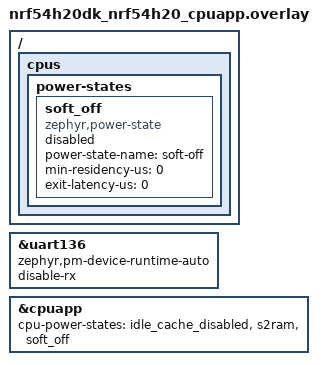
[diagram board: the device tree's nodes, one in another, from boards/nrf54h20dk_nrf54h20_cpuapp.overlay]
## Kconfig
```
# Copyright (c) 2021 Nordic Semiconductor ASA
# SPDX-License-Identifier: Apache-2.0

mainmenu "Nordic SYSTEM_OFF demo"

config APP_USE_RETAINED_MEM
	bool "Use state retention in system off using retained_mem driver"
	select RETAINED_MEM

config GRTC_WAKEUP_ENABLE
	bool "Use GRTC to wake up device from system off"
	default n
	help
	  Switch wake up source from pressing sw0 button to GRTC

source "Kconfig.zephyr"
```

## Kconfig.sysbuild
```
# Copyright 2024 Nordic Semiconductor ASA
#
# SPDX-License-Identifier: Apache-2.0

source "share/sysbuild/Kconfig"

config REMOTE_CORE_BOARD
string
	default "nrf54h20dk/nrf54h20/cpurad" if $(BOARD) = "nrf54h20dk"
```

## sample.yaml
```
sample:
  name: Low Power State Sample for nRF5x
common:
  tags: power
tests:
  sample.boards.nrf.system_off:
    integration_platforms:
      - nrf52840dk/nrf52840
    platform_allow:
      - nrf51dk/nrf51822
      - nrf52840dk/nrf52840
      - nrf52dk/nrf52832
      - nrf5340dk/nrf5340/cpuapp
      - nrf54l15dk/nrf54l05/cpuapp
      - nrf54l15dk/nrf54l10/cpuapp
      - nrf54l15dk/nrf54l15/cpuapp
      - nrf54lm20dk/nrf54lm20a/cpuapp
      - nrf54lm20dk/nrf54lm20b/cpuapp
      - nrf7120dk/nrf7120/cpuapp
    harness: console
    harness_config:
      type: multi_line
      ordered: true
      regex:
        - "system off demo"
        - "Retained data not supported"
        - "Entering system off; press sw0 to restart"
  sample.boards.nrf.system_off.retained_mem:
    integration_platforms:
      - nrf52840dk/nrf52840
    platform_allow:
      - nrf52840dk/nrf52840
      - nrf52dk/nrf52832
      - nrf5340dk/nrf5340/cpuapp
      - nrf54l15dk/nrf54l05/cpuapp
      - nrf54l15dk/nrf54l10/cpuapp
      - nrf54l15dk/nrf54l15/cpuapp
      - nrf54lm20dk/nrf54lm20a/cpuapp
      - nrf54lm20dk/nrf54lm20b/cpuapp
      - nrf7120dk/nrf7120/cpuapp
    extra_configs:
      - CONFIG_APP_USE_RETAINED_MEM=y
    harness: console
    harness_config:
      type: multi_line
      ordered: true
      regex:
        - "system off demo"
        - "Retained data: valid"
        - "Boot count: 1"
        - "Off count: 0"
        - "Active Ticks:"
        - "Entering system off; press sw0 to restart"
  sample.boards.nrf.system_off.grtc_off:
    platform_allow:
      - nrf54l15dk/nrf54l05/cpuapp
      - nrf54l15dk/nrf54l10/cpuapp
      - nrf54l15dk/nrf54l15/cpuapp
      - nrf54lm20dk/nrf54lm20a/cpuapp
      - nrf54lm20dk/nrf54lm20b/cpuapp
      - nrf7120dk/nrf7120/cpuapp
    extra_configs:
      - CONFIG_SYS_CLOCK_DISABLE=y
    harness: console
    harness_config:
      type: multi_line
      ordered: true
      regex:
        - "system off demo"
        - "Retained data not supported"
        - "System clock will be disabled"
        - "Entering system off; press sw0 to restart"
  sample.boards.nrf.system_off.retained_mem.grtc_off:
    platform_allow:
      - nrf54l15dk/nrf54l05/cpuapp
      - nrf54l15dk/nrf54l10/cpuapp
      - nrf54l15dk/nrf54l15/cpuapp
      - nrf54lm20dk/nrf54lm20a/cpuapp
      - nrf54lm20dk/nrf54lm20b/cpuapp
      - nrf7120dk/nrf7120/cpuapp
    extra_configs:
      - CONFIG_APP_USE_RETAINED_MEM=y
      - CONFIG_SYS_CLOCK_DISABLE=y
    harness: console
    harness_config:
      type: multi_line
      ordered: true
      regex:
        - "system off demo"
        - "Retained data: valid"
        - "Boot count: 1"
        - "Off count: 0"
        - "Active Ticks:"
        - "System clock will be disabled"
        - "Entering system off; press sw0 to restart"
  sample.boards.nrf.system_off.grtc_wakeup:
    platform_allow:
      - nrf54l15dk/nrf54l05/cpuapp
      - nrf54l15dk/nrf54l10/cpuapp
      - nrf54l15dk/nrf54l15/cpuapp
      - nrf54lm20dk/nrf54lm20a/cpuapp
      - nrf54lm20dk/nrf54lm20b/cpuapp
      - nrf7120dk/nrf7120/cpuapp
    extra_configs:
      - CONFIG_GRTC_WAKEUP_ENABLE=y
      - CONFIG_GPIO_WAKEUP_ENABLE=n
    harness: console
    harness_config:
      type: multi_line
      ordered: true
      regex:
        - "system off demo"
        - "Retained data not supported"
        - "Entering system off; wait 2 seconds to restart"
        - "system off demo"
        - "Retained data not supported"
        - "Entering system off; wait 2 seconds to restart"
        - "system off demo"
        - "Wakeup from System OFF by GRTC."
        - "Retained data not supported"
        - "Entering system off; wait 2 seconds to restart"
  sample.boards.nrf.system_off.retained_mem.grtc_wakeup:
    platform_allow:
      - nrf54l15dk/nrf54l05/cpuapp
      - nrf54l15dk/nrf54l10/cpuapp
      - nrf54l15dk/nrf54l15/cpuapp
      - nrf54lm20dk/nrf54lm20a/cpuapp
      - nrf54lm20dk/nrf54lm20b/cpuapp
      - nrf7120dk/nrf7120/cpuapp
    extra_configs:
      - CONFIG_APP_USE_RETAINED_MEM=y
      - CONFIG_GRTC_WAKEUP_ENABLE=y
      - CONFIG_GPIO_WAKEUP_ENABLE=n
    harness: console
    harness_config:
      type: multi_line
      ordered: true
      regex:
        - "system off demo"
        - "Retained data: valid"
        - "Boot count: 1"
        - "Off count: 0"
        - "Active Ticks:"
        - "Entering system off; wait 2 seconds to restart"
        - "system off demo"
        - "Retained data: valid"
        - "Boot count: 2"
        - "Off count: 1"
        - "Active Ticks:"
        - "Entering system off; wait 2 seconds to restart"
        - "Wakeup from System OFF by GRTC."
  sample.boards.nrf.system_off.retained_mem.tfm:
    sysbuild: true
    integration_platforms:
      - nrf7120dk/nrf7120/cpuapp/ns
    platform_allow:
      - nrf7120dk/nrf7120/cpuapp/ns
    extra_configs:
      - CONFIG_APP_USE_RETAINED_MEM=y
      - CONFIG_GRTC_WAKEUP_ENABLE=y
      - CONFIG_GPIO_WAKEUP_ENABLE=n
    harness: console
    harness_config:
      type: multi_line
      ordered: true
      regex:
        - "system off demo"
        - "Retained data: valid"
        - "Boot count: 1"
        - "Off count: 0"
        - "Active Ticks:"
        - "Entering system off; wait 2 seconds to restart"
        - "system off demo"
        - "Retained data: valid"
        - "Boot count: 2"
        - "Off count: 1"
        - "Active Ticks:"
        - "Entering system off; wait 2 seconds to restart"
        - "Wakeup from System OFF by GRTC."
  sample.boards.nrf.system_off.lpcomp_wakeup:
    extra_args: DTC_OVERLAY_FILE="boards/nrf54l15dk_nrf54l15_cpuapp_comparator.overlay"
    platform_allow:
      - nrf54l15dk/nrf54l15/cpuapp
    extra_configs:
      - CONFIG_LPCOMP_WAKEUP_ENABLE=y
      - CONFIG_GPIO_WAKEUP_ENABLE=n
      - CONFIG_COMPARATOR=y
    harness: console
    harness_config:
      type: multi_line
      ordered: true
      regex:
        - "system off demo"
        - "Retained data not supported"
        - "Entering system off; change signal level at comparator input to restart"
  sample.boards.nrf.system_off.retained_mem.lpcomp_wakeup:
    extra_args:
      - "DTC_OVERLAY_FILE=
         boards/nrf54l15dk_nrf54l15_cpuapp_comparator.overlay;
         boards/nrf54l15dk_nrf54l15_cpuapp.overlay"
    platform_allow:
      - nrf54l15dk/nrf54l15/cpuapp
    extra_configs:
      - CONFIG_APP_USE_RETAINED_MEM=y
      - CONFIG_GPIO_WAKEUP_ENABLE=n
      - CONFIG_LPCOMP_WAKEUP_ENABLE=y
      - CONFIG_RETAINED_MEM=y
      - CONFIG_COMPARATOR=y
    harness: console
    harness_config:
      type: multi_line
      ordered: true
      regex:
        - "system off demo"
        - "Retained data: valid"
        - "Boot count: 1"
        - "Off count: 0"
        - "Active Ticks:"
        - "Entering system off; change signal level at comparator input to restart"
```

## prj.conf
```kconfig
CONFIG_PM=y
CONFIG_PM_DEVICE=y
CONFIG_PM_DEVICE_RUNTIME=y
CONFIG_UART_ASYNC_API=y
CONFIG_GPIO=y
CONFIG_CRC=y
CONFIG_POWEROFF=y
CONFIG_HWINFO=y
```

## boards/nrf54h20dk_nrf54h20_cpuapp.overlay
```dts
&uart136 {
	zephyr,pm-device-runtime-auto;
	disable-rx;
};

/ {
	cpus {
		power-states {
			soft_off: soft_off {
			compatible = "zephyr,power-state";
			power-state-name = "soft-off";
			min-residency-us = <0>;
			exit-latency-us = <0>;
			status = "disabled";
			};
		};
	};
};

&cpuapp {
	cpu-power-states = <&idle_cache_disabled &s2ram &soft_off>;
};
```

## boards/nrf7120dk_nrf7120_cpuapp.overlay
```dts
/*
 * Copyright (c) 2026 Nordic Semiconductor ASA
 *
 * SPDX-License-Identifier: Apache-2.0
 */

/ {
	cpuapp_sram@2002e000 {
		compatible = "zephyr,memory-region", "mmio-sram";
		reg = <0x2002e000 DT_SIZE_K(4)>;
		zephyr,memory-region = "RetainedMem";
		status = "okay";

		retainedmem0: retainedmem {
			compatible = "zephyr,retained-ram";
			status = "okay";
		};
	};

	aliases {
		retainedmemdevice = &retainedmem0;
	};
};

&cpuapp_sram_app {
	/* Shrink SRAM size to avoid overlap with retained memory region */
	reg = <0x5060 (DT_SIZE_K(184) - 0x5060)>;
};
```

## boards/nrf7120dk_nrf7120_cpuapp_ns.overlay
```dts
/*
 * Copyright (c) 2026 Nordic Semiconductor ASA
 *
 * SPDX-License-Identifier: Apache-2.0
 */

/ {
	chosen {
		zephyr,sram = &app_sram;
	};

	app_sram: memory@20020000 {
		compatible = "mmio-sram";
		reg = <0x20020000 0x98000>;
	};

	retained_ram: memory@200b8000 {
		compatible = "zephyr,memory-region", "mmio-sram";
		reg = <0x200b8000 DT_SIZE_K(4)>;
		zephyr,memory-region = "RetainedMem";
		status = "okay";

		retainedmem0: retainedmem {
			compatible = "zephyr,retained-ram";
			status = "okay";
		};
	};

	aliases {
		retainedmemdevice = &retainedmem0;
	};
};
```

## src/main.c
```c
/*
 * Copyright (c) 2019 Nordic Semiconductor ASA
 *
 * SPDX-License-Identifier: Apache-2.0
 */

#include "retained.h"

#include <inttypes.h>
#include <stdio.h>

#include <zephyr/device.h>
#include <zephyr/drivers/gpio.h>
#include <zephyr/drivers/hwinfo.h>
#include <zephyr/drivers/comparator.h>
#include <zephyr/kernel.h>
#include <zephyr/pm/pm.h>
#include <zephyr/pm/device.h>
#include <zephyr/sys/poweroff.h>
#include <zephyr/sys/util.h>

#define NON_WAKEUP_RESET_REASON (RESET_PIN | RESET_SOFTWARE | RESET_POR | RESET_DEBUG)
#include <zephyr/pm/device_runtime.h>
#include <hal/nrf_gpio.h>
#include <hal/nrf_memconf.h>

#if defined(CONFIG_GRTC_WAKEUP_ENABLE)
#include <zephyr/drivers/timer/nrf_grtc_timer.h>
#define DEEP_SLEEP_TIME_S 2
#endif
#if defined(CONFIG_GPIO_WAKEUP_ENABLE)
static const struct gpio_dt_spec sw0 = GPIO_DT_SPEC_GET(DT_ALIAS(sw0), gpios);
static const uint32_t port_sw0 = DT_PROP(DT_GPIO_CTLR_BY_IDX(DT_ALIAS(sw0), gpios, 0), port);
#endif
#if defined(CONFIG_LPCOMP_WAKEUP_ENABLE)
static const struct device *comp_dev = DEVICE_DT_GET(DT_NODELABEL(comp));
#endif

static const struct gpio_dt_spec sw1 = GPIO_DT_SPEC_GET(DT_ALIAS(sw1), gpios);
static const uint32_t port_sw1 = DT_PROP(DT_GPIO_CTLR_BY_IDX(DT_ALIAS(sw1), gpios, 0), port);

int print_reset_cause(uint32_t reset_cause)
{
	int32_t ret;
	uint32_t supported;

	ret = hwinfo_get_supported_reset_cause((uint32_t *)&supported);

	if (ret) {
		printk("Reset cause 0x%08X not supported ret %d.\n", reset_cause, ret);
		return -ENOTSUP;
	}

	if (reset_cause & RESET_DEBUG) {
		printf("Reset by debugger.\n");
	} else if (reset_cause & RESET_CLOCK) {
		printf("Wakeup from System OFF by GRTC.\n");
	} else if (reset_cause & RESET_LOW_POWER_WAKE) {
		printf("Wakeup from System OFF by GPIO.\n");
	} else if (reset_cause & RESET_PIN) {
		printf("Reset by external pin.\n");
	} else if (reset_cause & RESET_SOFTWARE) {
		printf("Reset by software.\n");
	} else if (reset_cause & RESET_POR || reset_cause == 0) {
		printf("Power on reset.\n");
	} else  {
		printf("Other wake up cause 0x%08X.\n", reset_cause);
	}

	return 0;
}

int main(void)
{
	int rc;
	uint32_t reset_cause;
	uint32_t nrf_pin_sw1 = 32 * port_sw1 + sw1.pin;
	bool do_poweroff = true;

	if (nrf_gpio_pin_latch_get(nrf_pin_sw1)) {
		nrf_gpio_pin_latch_clear(nrf_pin_sw1);
#if defined(CONFIG_SOC_NRF54H20)
		/* Set gpio default if sense is set, prevent 300uA additional current after wakeup
		 * This is only needed for nrf54 series as PIN config is different from PAD config.
		 * After wakeup from system-off, SENSE bit is not reset but INPUT is.
		 */
		if (nrf_gpio_pin_sense_get(nrf_pin_sw1) != GPIO_PIN_CNF_SENSE_Disabled) {
			nrf_gpio_cfg_default(nrf_pin_sw1);
		}
#endif
		do_poweroff = false;
	}

	printf("\n%s system off demo\n", CONFIG_BOARD_QUALIFIERS);
	hwinfo_get_reset_cause(&reset_cause);
	rc = print_reset_cause(reset_cause);

#if defined(CONFIG_SOC_NRF54H20)
#if defined(CONFIG_GPIO_WAKEUP_ENABLE)
	/* Set gpio default if sense is set, prevent 300uA additional current after wakeup
	 * This is only needed for nrf54 series as PIN config is different from PAD config.
	 * After wakeup from system-off, SENSE bit is not reset but INPUT is.
	 */
	uint32_t nrf_pin_sw0 = 32 * port_sw0 + sw0.pin;
	if(nrf_gpio_pin_sense_get(nrf_pin_sw0) != GPIO_PIN_CNF_SENSE_Disabled) {
		nrf_gpio_cfg_default(nrf_pin_sw0);
	}
#endif
#endif

	if (rc < 0) {
		printf("Reset cause not supported.\n");
		return 0;
	}

	if (IS_ENABLED(CONFIG_APP_USE_RETAINED_MEM)) {
		bool retained_ok = retained_validate();

		if (reset_cause & NON_WAKEUP_RESET_REASON) {
			retained.boots = 0;
			retained.off_count = 0;
			retained.uptime_sum = 0;
			retained.uptime_latest = 0;
			retained_ok = true;
		}
		/* Increment for this boot attempt and update. */
		retained.boots += 1;
		retained_update();

		printf("Retained data: %s\n", retained_ok ? "valid" : "INVALID");
		printf("Boot count: %u\n", retained.boots);
		printf("Off count: %u\n", retained.off_count);
		printf("Active Ticks: %" PRIu64 "\n", retained.uptime_sum);
	} else {
		printf("Retained data not supported\n");
	}

	k_sleep(K_MSEC(4000));

#if defined(CONFIG_GRTC_WAKEUP_ENABLE)

	int err = z_nrf_grtc_wakeup_prepare(DEEP_SLEEP_TIME_S * USEC_PER_SEC);

	if (err < 0) {
		printf("Unable to prepare GRTC as a wake up source (err = %d).\n", err);
	} else {
		printf("Entering system off; wait %u seconds to restart\n", DEEP_SLEEP_TIME_S);
	}
#endif
#if defined(CONFIG_GPIO_WAKEUP_ENABLE)
	/* configure sw0 as input, interrupt as level active to allow wake-up */
	rc = gpio_pin_configure_dt(&sw0, GPIO_INPUT);
	if (rc < 0) {
		printf("Could not configure sw0 GPIO (%d)\n", rc);
		return 0;
	}

	rc = gpio_pin_interrupt_configure_dt(&sw0, GPIO_INT_LEVEL_ACTIVE);
	if (rc < 0) {
		printf("Could not configure sw0 GPIO interrupt (%d)\n", rc);
		return 0;
	}

#if defined(CONFIG_SOC_NRF54H20)
	nrf_gpio_pin_retain_disable(nrf_pin_sw0);
#endif
#endif
#if defined(CONFIG_LPCOMP_WAKEUP_ENABLE)
	comparator_set_trigger(comp_dev, COMPARATOR_TRIGGER_BOTH_EDGES);
	comparator_trigger_is_pending(comp_dev);
	printf("Entering system off; change signal level at comparator input to restart\n");
#endif
	rc = gpio_pin_configure_dt(&sw1, GPIO_INPUT);
	if (rc < 0) {
		printf("Could not configure sw1 GPIO (%d)\n", rc);
		return 0;
	}

	rc = gpio_pin_interrupt_configure_dt(&sw1, GPIO_INT_LEVEL_ACTIVE);
	if (rc < 0) {
		printf("Could not configure sw0 GPIO interrupt (%d)\n", rc);
		return 0;
	}

#if defined(CONFIG_SOC_NRF54H20)
	nrf_gpio_pin_retain_disable(nrf_pin_sw1);
#endif

	if (do_poweroff) {
		printf("Entering system off; press sw0 or sw1 to restart\n");
	} else {
		printf("Button sw1 pressed, not entering system off\n");
	}

	if (IS_ENABLED(CONFIG_PM_DEVICE) && IS_ENABLED(CONFIG_SERIAL)) {
		static const struct device *cons = DEVICE_DT_GET(DT_CHOSEN(zephyr_console));
		int err;
		enum pm_device_state state;

		if (cons) {
			do {
				err = pm_device_state_get(cons, &state);
			} while ((err == 0) && (state == PM_DEVICE_STATE_ACTIVE));
		}
	}

	if (IS_ENABLED(CONFIG_APP_USE_RETAINED_MEM)) {
		/* Update the retained state */
		retained.off_count += 1;
		retained_update();
	}


	if (do_poweroff) {
#if CONFIG_SOC_NRF54H20_CPUAPP
		/* Local RAM0 (TCM) is currently not used so retention can be disabled. */
		nrf_memconf_ramblock_ret_mask_enable_set(NRF_MEMCONF, 0, RAMBLOCK_RET_MASK, false);
		nrf_memconf_ramblock_ret_mask_enable_set(NRF_MEMCONF, 1, RAMBLOCK_RET_MASK, false);
#endif

		while (1) {
			pm_state_force(0u, &(struct pm_state_info){PM_STATE_SOFT_OFF, 0, 0});
			k_sleep(K_SECONDS(8));
			printk("Woke up from system off with current context, retrying...\n");
		}
	} else {
		k_sleep(K_FOREVER);
	}

	hwinfo_clear_reset_cause();
	pm_state_force(0u, &(struct pm_state_info){PM_STATE_SOFT_OFF, 0, 0});
	k_sleep(K_FOREVER);

	return 0;
}
```
